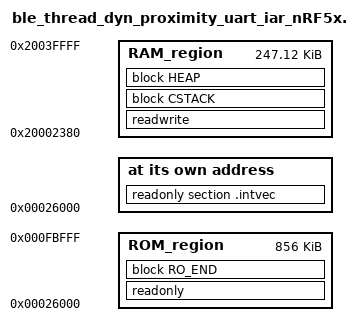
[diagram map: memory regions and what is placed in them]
/*###ICF### Section handled by ICF editor, don't touch! ****/
/*-Editor annotation file-*/
/* IcfEditorFile="$TOOLKIT_DIR$\config\ide\IcfEditor\cortex_v1_0.xml" */
/*-Specials-*/
define symbol __ICFEDIT_intvec_start__ = 0x26000;
/*-Memory Regions-*/
define symbol __ICFEDIT_region_ROM_start__   = 0x26000;
define symbol __ICFEDIT_region_ROM_end__     = 0xfbfff;
define symbol __ICFEDIT_region_RAM_start__   = 0x20002380;
define symbol __ICFEDIT_region_RAM_end__     = 0x2003ffff;
export symbol __ICFEDIT_region_RAM_start__;
export symbol __ICFEDIT_region_RAM_end__;
/*-Sizes-*/
define symbol __ICFEDIT_size_cstack__   = 8192;
define symbol __ICFEDIT_size_heap__     = 0;
/**** End of ICF editor section. ###ICF###*/

define memory mem with size = 4G;
define region ROM_region   = mem:[from __ICFEDIT_region_ROM_start__   to __ICFEDIT_region_ROM_end__];
define region RAM_region   = mem:[from __ICFEDIT_region_RAM_start__   to __ICFEDIT_region_RAM_end__];

define symbol __region_ot_flash_data_start = 0xfc000;
define symbol __region_ot_flash_data_length = 0x4000;
define symbol __start_ot_flash_data = __region_ot_flash_data_start;
define symbol __stop_ot_flash_data = __region_ot_flash_data_start + __region_ot_flash_data_length;
export symbol __start_ot_flash_data;
export symbol __stop_ot_flash_data;

define block CSTACK    with alignment = 8, size = __ICFEDIT_size_cstack__   { };
define block HEAP      with alignment = 8, size = __ICFEDIT_size_heap__     { };
define block RO_END    with alignment = 8, size = 0     { };

initialize by copy { readwrite };
do not initialize  { section .noinit };

keep { section .intvec };
place at address mem:__ICFEDIT_intvec_start__ { readonly section .intvec };
place in ROM_region   { readonly,
                        block RO_END };
place in RAM_region   { readwrite,
                        block CSTACK,
                        block HEAP };

